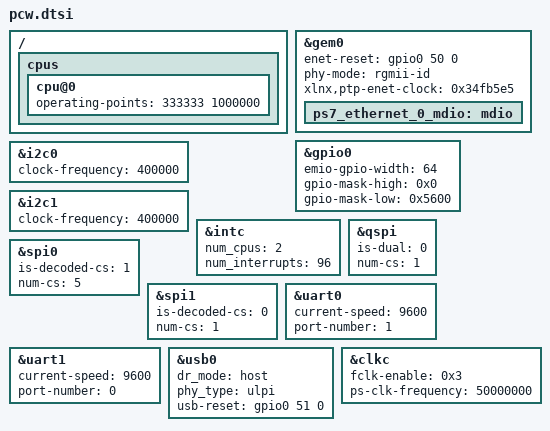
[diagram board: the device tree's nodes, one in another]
/* R. Assiro
 * CAUTION: This file is automatically generated by Xilinx.
 * Version: HSI 
 * Today is: Tue Mar 15 19:54:51 2016
*/


/ {
	cpus {
		cpu@0 {
			operating-points = <333333 1000000>;
		};
	};
};
&gem0 {
	enet-reset = <&gpio0 50 0>;
	phy-mode = "rgmii-id";
	status = "okay";
	xlnx,ptp-enet-clock = <0x34fb5e5>;
	ps7_ethernet_0_mdio: mdio {
		#address-cells = <1>;
		#size-cells = <0>;
	};
};
&gpio0 {
	emio-gpio-width = <64>;
	gpio-mask-high = <0x0>;
	gpio-mask-low = <0x5600>;
};
&i2c0 {
	clock-frequency = <400000>;
	status = "okay";
};
&i2c1 {
	clock-frequency = <400000>;
	status = "okay";
};
&intc {
	num_cpus = <2>;
	num_interrupts = <96>;
};
&qspi {
	is-dual = <0>;
	num-cs = <1>;
	status = "okay";
};
&spi0 {
	is-decoded-cs = <1>;
	num-cs = <5>;
	status = "okay";
};

&spi1 {
	is-decoded-cs = <0>;
	num-cs = <1>;
	status = "okay";
};

&uart0 {
	current-speed = <9600>;
	device_type = "serial";
	port-number = <1>;
	status = "okay";
};
&uart1 {
	current-speed = <9600>;
	device_type = "serial";
	port-number = <0>;
	status = "okay";
};
&usb0 {
	dr_mode = "host";
	phy_type = "ulpi";
	status = "okay";
	usb-reset = <&gpio0 51 0>;
};
&clkc {
	fclk-enable = <0x3>;
	ps-clk-frequency = <50000000>;
};
